# f2838x_dev_cfg_regs register map
Vendor: Texas Instruments
Peripheral module from a debugger description file (folder C2000).
Address unit: 16 bits
Registers are 32-bit, read-write, no defined reset value unless marked. A register's access mark holds for its fields unless they carry their own. Offsets are as the file gives them; lines under a group give offsets from that group; [hi:lo] are bit positions; {n}, {i} and the like mark numbered series; 'fields as' and 'values as' point back to an identical list; <NAME> marks a mode.

## DEV_CFG_REGS — DEV CFG Registers
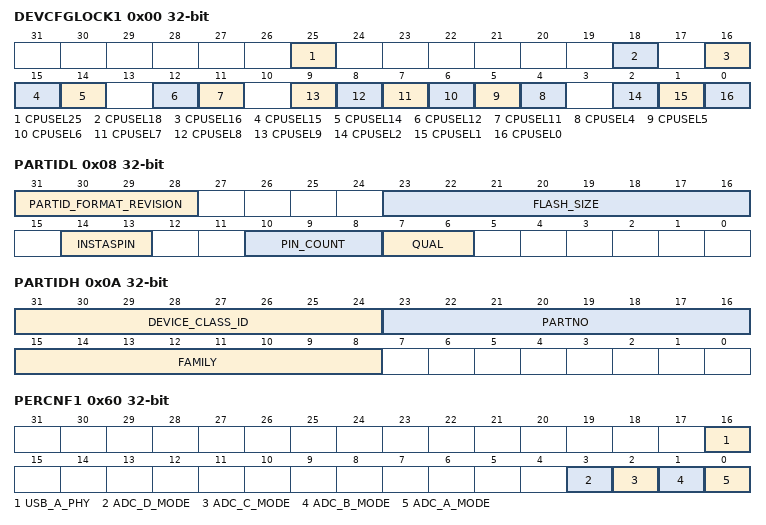
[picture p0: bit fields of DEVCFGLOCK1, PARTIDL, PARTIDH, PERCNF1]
0x00 DEVCFGLOCK1 — Lock bit for DEVCFG registers
  [25] CPUSEL25 — Lock bit for CPUSEL25 register
  [18] CPUSEL18 — Lock bit for CPUSEL18 register
  [16] CPUSEL16 — Lock bit for CPUSEL16 register
  [15] CPUSEL15 — Lock bit for CPUSEL15 register
  [14] CPUSEL14 — Lock bit for CPUSEL14 register
  [12] CPUSEL12 — Lock bit for CPUSEL12 register
  [11] CPUSEL11 — Lock bit for CPUSEL11 register
  [n] CPUSEL{n} (n=4..9) — Lock bit for CPUSEL{n} register
  [2] CPUSEL2 — Lock bit for CPUSEL2 register
  [1] CPUSEL1 — Lock bit for CPUSEL1 register
  [0] CPUSEL0 — Lock bit for CPUSEL0 register
0x02 DEVCFGLOCK2 access not given — Lock bit for DEVCFG registers
0x08 PARTIDL — Lower 32-bit of Device PART Identification Number
  [31:28] PARTID_FORMAT_REVISION — Revision of the PARTID format
  [23:16] FLASH_SIZE — Flash size in KB
  [14:13] INSTASPIN — Motorware feature set
  [10:8] PIN_COUNT — Device Pin Count
  [7:6] QUAL — Qualification Status
0x0A PARTIDH access per field — Upper 32-bit of Device PART Identification Number
  [31:24] DEVICE_CLASS_ID ro
  [23:16] PARTNO rw — Device part number
  [15:8] FAMILY rw — Device family
0x0C REVID ro — Device Revision Number
  [15:0] REVID — Device Revision ID. This is specific to the Device
0x60 PERCNF1 — Peripheral Configuration register
  [16] USB_A_PHY — USB_A_PHY enable/disable bit
  [3] ADC_D_MODE — ADC Wrapper-4 mode setting bit
  [2] ADC_C_MODE — ADC Wrapper-3 mode setting bit
  [1] ADC_B_MODE — ADC Wrapper-2 mode setting bit
  [0] ADC_A_MODE — ADC Wrapper-1 mode setting bit
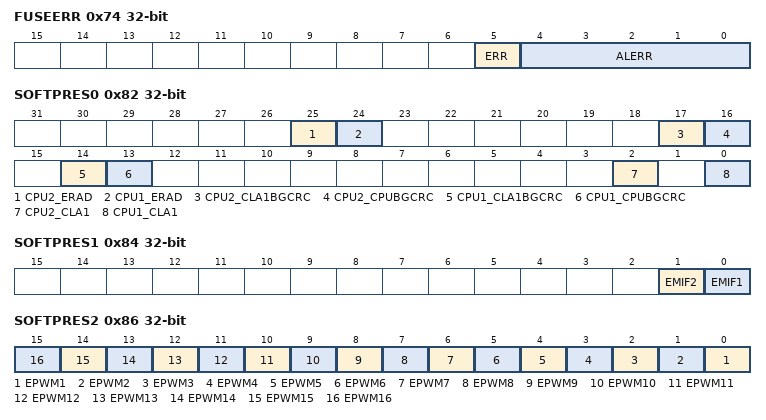
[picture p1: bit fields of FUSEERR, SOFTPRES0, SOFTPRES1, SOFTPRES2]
0x74 FUSEERR ro — e-Fuse error Status register
  [5] ERR — Efuse Self Test Error Status
  [4:0] ALERR — Efuse Autoload Error Status
0x82 SOFTPRES0 — Processing Block Software Reset register
  [25] CPU2_ERAD — ERAD Module reset bit
  [24] CPU1_ERAD — ERAD Module reset bit
  [17] CPU2_CLA1BGCRC — CLA1BGCRC Module reset bit
  [16] CPU2_CPUBGCRC — CPUBGCRC Module reset bit
  [14] CPU1_CLA1BGCRC — CLA1BGCRC Module reset bit
  [13] CPU1_CPUBGCRC — CPUBGCRC Module reset bit
  [2] CPU2_CLA1 — CPU2_CLA1 software reset bit
  [0] CPU1_CLA1 — CPU1_CLA1 software reset bit
0x84 SOFTPRES1 — EMIF Software Reset register
  [1] EMIF2 — EMIF2 software reset bit
  [0] EMIF1 — EMIF1 software reset bit
0x86 SOFTPRES2 — Peripheral Software Reset register
  [n-1] EPWM{n} (n=1..16) — EPWM{n} software reset bit
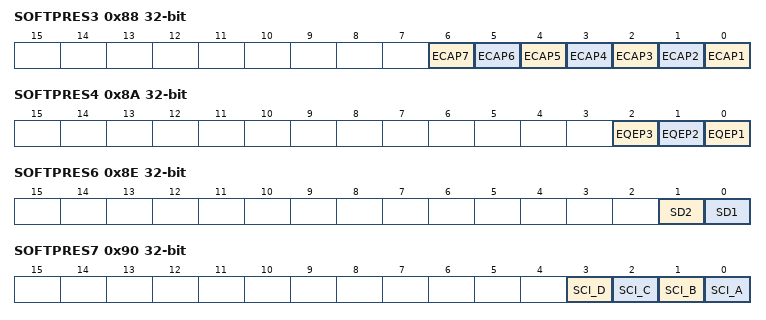
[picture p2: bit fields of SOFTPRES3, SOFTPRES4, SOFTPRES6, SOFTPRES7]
0x88 SOFTPRES3 — Peripheral Software Reset register
  [n-1] ECAP{n} (n=1..7) — ECAP{n} software reset bit
0x8A SOFTPRES4 — Peripheral Software Reset register
  [2] EQEP3 — EQEP3 software reset bit
  [1] EQEP2 — EQEP2 software reset bit
  [0] EQEP1 — EQEP1 software reset bit
0x8E SOFTPRES6 — Peripheral Software Reset register
  [1] SD2 — SD2 software reset bit
  [0] SD1 — SD1 software reset bit
0x90 SOFTPRES7 — Peripheral Software Reset register
  [3] SCI_D — SCI_D software reset bit
  [2] SCI_C — SCI_C software reset bit
  [1] SCI_B — SCI_B software reset bit
  [0] SCI_A — SCI_A software reset bit
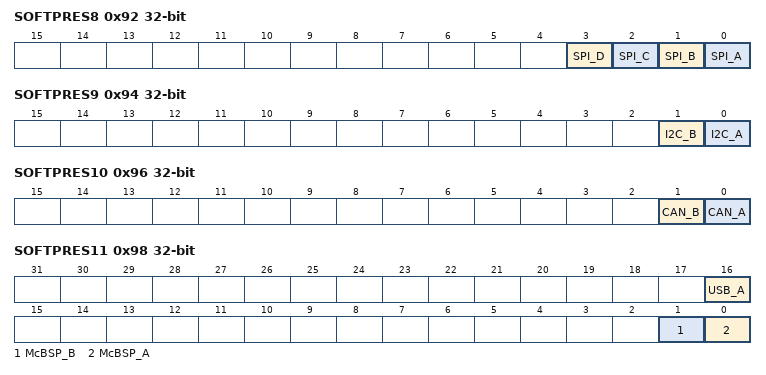
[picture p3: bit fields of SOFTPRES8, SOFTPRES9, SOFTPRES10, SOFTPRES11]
0x92 SOFTPRES8 — Peripheral Software Reset register
  [3] SPI_D — SPI_D software reset bit
  [2] SPI_C — SPI_C software reset bit
  [1] SPI_B — SPI_B software reset bit
  [0] SPI_A — SPI_A software reset bit
0x94 SOFTPRES9 — Peripheral Software Reset register
  [1] I2C_B — I2C_B software reset bit
  [0] I2C_A — I2C_A software reset bit
0x96 SOFTPRES10 — Peripheral Software Reset register
  [1] CAN_B — CAN_B software reset bit
  [0] CAN_A — CAN_A software reset bit
0x98 SOFTPRES11 — Peripheral Software Reset register
  [16] USB_A — USB_A software reset bit
  [1] McBSP_B — McBSP_B software reset bit
  [0] McBSP_A — McBSP_A software reset bit
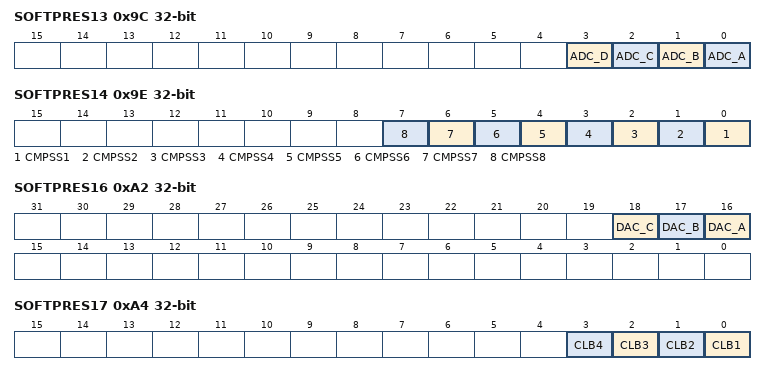
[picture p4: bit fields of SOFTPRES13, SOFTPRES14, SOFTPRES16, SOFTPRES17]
0x9C SOFTPRES13 — Peripheral Software Reset register
  [3] ADC_D — ADC_D software reset bit
  [2] ADC_C — ADC_C software reset bit
  [1] ADC_B — ADC_B software reset bit
  [0] ADC_A — ADC_A software reset bit
0x9E SOFTPRES14 — Peripheral Software Reset register
  [n-1] CMPSS{n} (n=1..8) — CMPSS{n} software reset bit
0xA2 SOFTPRES16 — Peripheral Software Reset register
  [18] DAC_C — Buffered_DAC12_3 software reset bit
  [17] DAC_B — Buffered_DAC12_2 software reset bit
  [16] DAC_A — Buffered_DAC12_1 software reset bit
0xA4 SOFTPRES17 — Reserved Peripheral Software Reset register
  [n-1] CLB{n} (n=1..4) — CLB{n} software reset bit
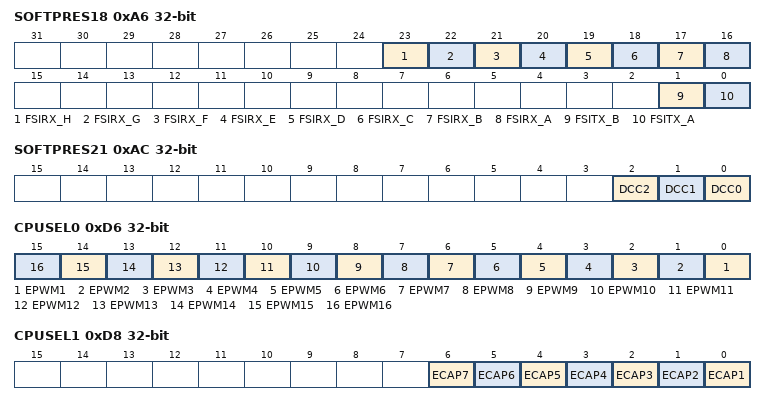
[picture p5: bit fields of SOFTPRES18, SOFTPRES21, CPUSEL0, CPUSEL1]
0xA6 SOFTPRES18 — Reserved Peripheral Software Reset register
  [23] FSIRX_H — FSIRX_H software reset bit
  [22] FSIRX_G — FSIRX_G software reset bit
  [21] FSIRX_F — FSIRX_F software reset bit
  [20] FSIRX_E — FSIRX_E software reset bit
  [19] FSIRX_D — FSIRX_D software reset bit
  [18] FSIRX_C — FSIRX_C software reset bit
  [17] FSIRX_B — FSIRX_B software reset bit
  [16] FSIRX_A — FSIRX_A software reset bit
  [1] FSITX_B — FSITX_B software reset bit
  [0] FSITX_A — FSITX_A software reset bit
0xAA SOFTPRES20 — Peripheral Software Reset register
  [0] PMBUS_A — PMBUS_A software reset bit
0xAC SOFTPRES21 — Peripheral Software Reset register
  [2] DCC2 — DCC2 Module reset bit
  [1] DCC1 — DCC1 Module reset bit
  [0] DCC0 — DCC0 Module reset bit
0xB0 SOFTPRES23 — Peripheral Software Reset register
  [0] ETHERCAT — ETHERCAT Module reset bit
0xD6 CPUSEL0 — CPU Select register for common peripherals
  [n-1] EPWM{n} (n=1..16) — EPWM{n} CPU select bit
0xD8 CPUSEL1 — CPU Select register for common peripherals
  [n-1] ECAP{n} (n=1..7) — ECAP{n} CPU select bit
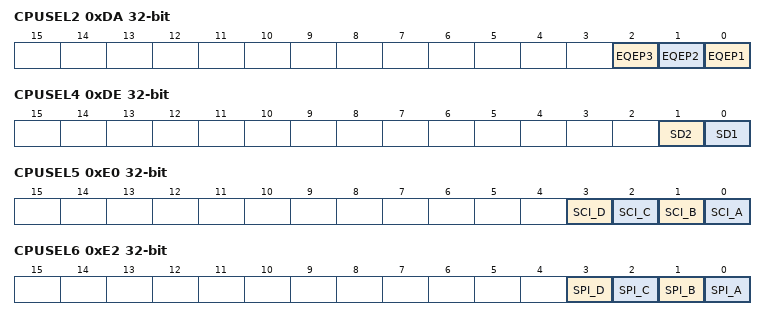
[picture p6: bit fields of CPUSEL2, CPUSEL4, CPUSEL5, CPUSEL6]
0xDA CPUSEL2 — CPU Select register for common peripherals
  [2] EQEP3 — EQEP3 CPU select bit
  [1] EQEP2 — EQEP2 CPU select bit
  [0] EQEP1 — EQEP1 CPU select bit
0xDE CPUSEL4 — CPU Select register for common peripherals
  [1] SD2 — SD2 CPU select bit
  [0] SD1 — SD1 CPU select bit
0xE0 CPUSEL5 — CPU Select register for common peripherals
  [3] SCI_D — SCI_D CPU select bit
  [2] SCI_C — SCI_C CPU select bit
  [1] SCI_B — SCI_B CPU select bit
  [0] SCI_A — SCI_A CPU select bit
0xE2 CPUSEL6 — CPU Select register for common peripherals
  [3] SPI_D — SPI_D CPU select bit
  [2] SPI_C — SPI_C CPU select bit
  [1] SPI_B — SPI_B CPU select bit
  [0] SPI_A — SPI_A CPU select bit
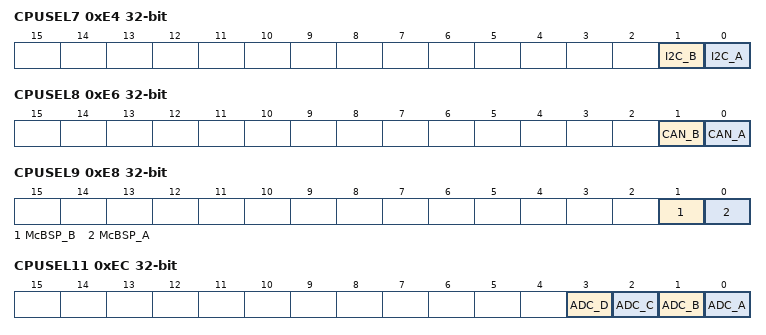
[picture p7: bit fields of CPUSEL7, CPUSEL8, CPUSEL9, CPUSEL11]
0xE4 CPUSEL7 — CPU Select register for common peripherals
  [1] I2C_B — I2C_B CPU select bit
  [0] I2C_A — I2C_A CPU select bit
0xE6 CPUSEL8 — CPU Select register for common peripherals
  [1] CAN_B — CAN_B CPU select bit
  [0] CAN_A — CAN_A CPU select bit
0xE8 CPUSEL9 — CPU Select register for common peripherals
  [1] McBSP_B — McBSP_B CPU select bit
  [0] McBSP_A — McBSP_A CPU select bit
0xEC CPUSEL11 — CPU Select register for common peripherals
  [3] ADC_D — ADC_D CPU select bit
  [2] ADC_C — ADC_C CPU select bit
  [1] ADC_B — ADC_B CPU select bit
  [0] ADC_A — ADC_A CPU select bit
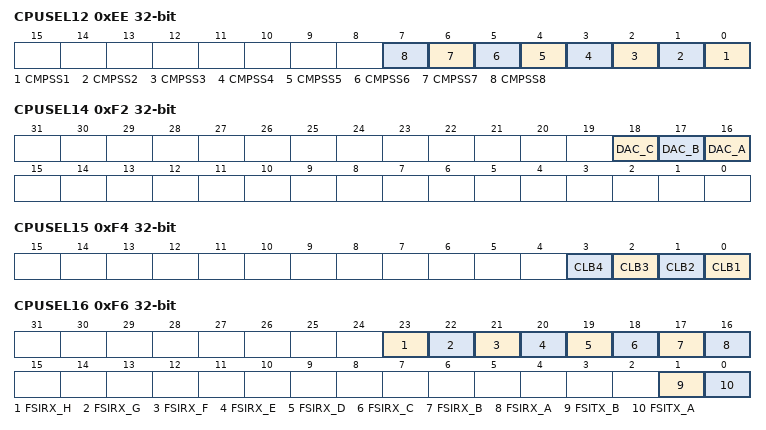
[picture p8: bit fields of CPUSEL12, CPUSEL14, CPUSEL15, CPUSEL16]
0xEE CPUSEL12 — CPU Select register for common peripherals
  [n-1] CMPSS{n} (n=1..8) — CMPSS{n} CPU select bit
0xF2 CPUSEL14 — CPU Select register for common peripherals
  [18] DAC_C — Buffered_DAC12_3 CPU select bit
  [17] DAC_B — Buffered_DAC12_2 CPU select bit
  [16] DAC_A — Buffered_DAC12_1 CPU select bit
0xF4 CPUSEL15 — CPU Select register for common peripherals
  [n-1] CLB{n} (n=1..4) — CLB{n} CPU select bit
0xF6 CPUSEL16 — CPU Select register for common peripherals
  [23] FSIRX_H — FSIRX_H CPU select bit
  [22] FSIRX_G — FSIRX_G CPU select bit
  [21] FSIRX_F — FSIRX_F CPU select bit
  [20] FSIRX_E — FSIRX_E CPU select bit
  [19] FSIRX_D — FSIRX_D CPU select bit
  [18] FSIRX_C — FSIRX_C CPU select bit
  [17] FSIRX_B — FSIRX_B CPU select bit
  [16] FSIRX_A — FSIRX_A CPU select bit
  [1] FSITX_B — FSITX_B CPU select bit
  [0] FSITX_A — FSITX_A CPU select bit
0xFA CPUSEL18 — CPU Select register for common peripherals
  [0] PMBUS_A — PMBUS_A CPU select bit
0x108 CPUSEL25 — CPU Select register for common peripherals
  [0] HRCAL — HRCAL CPU select bit
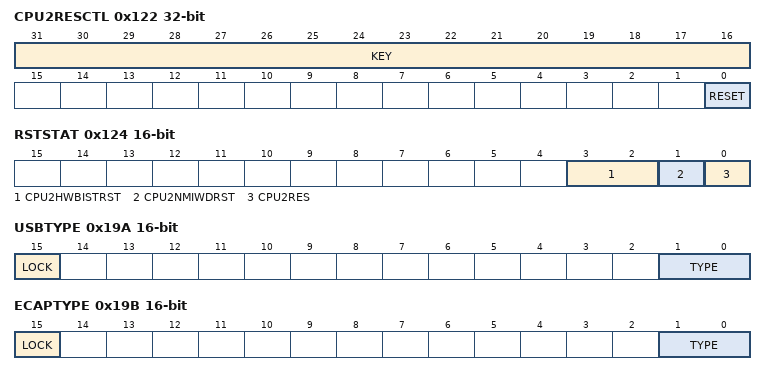
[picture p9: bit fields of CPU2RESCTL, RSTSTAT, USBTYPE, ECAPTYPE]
0x122 CPU2RESCTL — CPU2 Reset Control Register
  [31:16] KEY — Key Qualifier for writes to this register
  [0] RESET — CPU2 Reset Control bit
0x124 RSTSTAT 16-bit access per field — Reset Status register for secondary C28x CPUs
  [3:2] CPU2HWBISTRST rw — Tells whether a HWBIST reset was issued to CPU2 or not
  [1] CPU2NMIWDRST rw — Tells whether a CPU2.NMIWD reset was issued to CPU2 or not
  [0] CPU2RES ro — CPU2 Reset Status bit
0x125 LPMSTAT 16-bit ro — LPM Status Register for secondary C28x CPUs
  [1:0] CPU2LPMSTAT — CPU2 LPM Status
0x184 BANKSEL — Configures the bank to programmed by CPU1.
  [1:0] SEL — Selects the BANK to be programmed by CPU1 FMC.
0x19A USBTYPE 16-bit — Configures USB Type for the device
  [15] LOCK — Lock bit
  [1:0] TYPE — Configure USB type
0x19B ECAPTYPE 16-bit — Configures ECAP Type for the device
  [15] LOCK — Lock bit
  [1:0] TYPE — Configure ECAP type
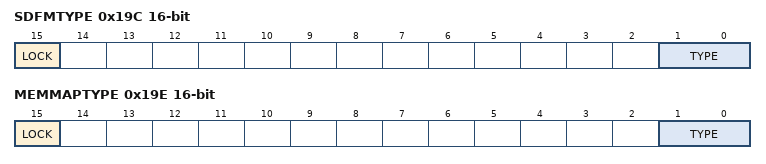
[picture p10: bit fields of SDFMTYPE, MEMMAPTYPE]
0x19C SDFMTYPE 16-bit — Configures SDFM Type for the device
  [15] LOCK — Lock bit
  [1:0] TYPE — Configure SDFM type
0x19E MEMMAPTYPE 16-bit — Configures Memory Map Type for the device
  [15] LOCK — Lock bit
  [1:0] TYPE — Configures system specific features related to memory map.
